# MB9AF31xK register map
Vendor: Cypress; File version: 2.1
MB9A310K Series package K
CPU: CM3 r2p1, little endian, MPU, no FPU, 4 interrupt priority bits
Registers are 32-bit, read-write, reset 0x0 unless marked. A register's access mark holds for its fields unless they carry their own. Offsets are from the block's base; lines under a group give offsets from that group; [hi:lo] are bit positions; {n}, {i} and the like mark numbered series; 'fields as' and 'values as' point back to an identical list; <NAME> marks a mode.

## Memory map
0x200E0000 WORKFLASH_IF size 0xC — WorkFlash Memory
0x40000000 FLASH_IF blocks up to offset 0x104 — Flash Memory
0x40000200 UNIQUE_ID size 0x8
0x40010000 CRG blocks up to offset 0x6C — Clock Unit Registers
0x40011000 HWWDT blocks up to offset 0xC04 — Hardware Watchdog Timer
0x40012000 SWWDT blocks up to offset 0xC04 — Software Watchdog Timer
0x40015000 DT blocks up to offset 0x3C — Dual Timer
0x40020000 MFT0 blocks up to offset 0xC2 — Multifunction Timer 0
0x40024000 MFT_PPG blocks up to offset 0x359 — PPG Configuration
0x40025000 BT0 blocks up to offset 0x12 — Base Timer 0
0x40025040 BT1 blocks up to offset 0x12 — Base Timer 1
0x40025080 BT2 blocks up to offset 0x12 — Base Timer 2
0x400250C0 BT3 blocks up to offset 0x12 — Base Timer 3
0x40025100 BTIOSEL03 blocks up to offset 0x2 — Base Timer I/O Select
0x40025200 BT4 blocks up to offset 0x12 — Base Timer 4
0x40025240 BT5 blocks up to offset 0x12 — Base Timer 5
0x40025280 BT6 blocks up to offset 0x12 — Base Timer 6
0x400252C0 BT7 blocks up to offset 0x12 — Base Timer 7
0x40025300 BTIOSEL47 blocks up to offset 0x2 — Base Timer I/O Select
0x40025F00 SBSSR blocks up to offset 0xFE — Software-based Simultaneous Startup Register
0x40026000 QPRC0 blocks up to offset 0x40 — Quadrature Position/Revolution Counter 0
0x40027000 ADC0 blocks up to offset 0x3D — ADC0 Registers
0x40027100 ADC1 blocks up to offset 0x3D — ADC1 Registers
0x4002E000 CRTRIM blocks up to offset 0x10 — CR Trimming Registers
0x40030000 EXTI blocks up to offset 0x1A — External Interrupt and NMI Control
0x40031000 INTREQ blocks up to offset 0x218 — Interrupts
0x40033000 GPIO blocks up to offset 0x740 — I/O Port Registers
0x40035000 LVD blocks up to offset 0x11 — Low-voltage Detection
0x40035100 DS blocks up to offset 0x810 — Low Power Consumption Mode
0x40036000 USBCLK blocks up to offset 0x31 — USB Clock
0x40038000 MFS0 blocks up to offset 0x1E — Multi-function Serial Interface 0
0x40038100 MFS1 blocks up to offset 0x1E — Multi-function Serial Interface 1
0x40038300 MFS3 blocks up to offset 0x1E — Multi-function Serial Interface 3
0x40038500 MFS5 blocks up to offset 0xE — Multi-function Serial Interface 5
0x40038800 MFS_NFC size 0x2 — I2C Auxiliary Noise Filter Setting Register
0x40039000 CRC blocks up to offset 0x10 — CRC Registers
0x4003A000 WC blocks up to offset 0x15 — Watch Counter
0x4003B000 RTC blocks up to offset 0x2A — REAL-TIME CLOCK
0x40040000 USB0 blocks up to offset 0x2176 — USB0 Function
0x40060000 DMAC blocks up to offset 0x90 — DMAC Registers

## Interrupts
0 CSV (CRG)
1 SWDT (SWWDT)
2 LVD
3 MFT0_2_WFG_DTIF (MFT0)
4 EXINT0_7 (EXTI)
5 EXINT8_31 (EXTI)
6 DT_QPRC0_2 (DT, QPRC0)
7 MFS0_RX (MFS0)
8 MFS0_TX (MFS0)
9 MFS1_RX (MFS1)
10 MFS1_TX (MFS1)
13 MFS3_RX (MFS3)
14 MFS3_TX (MFS3)
17 MFS5_RX (MFS5)
18 MFS5_TX (MFS5)
23 PPG00_02_04_08_10_12_16_18_20 (MFT_PPG)
24 TIM_WC_RTC (CRG, WC, RTC)
25 ADC0
26 ADC1
28 MFT0_2_FRT (MFT0)
29 MFT0_2_ICU (MFT0)
30 MFT0_2_OCU (MFT0)
31 BT0_7 (BT{n} (n=0..7))
34 USB0_F (USB0)
35 USB0_H_F (USB0)
{n+38} DMAC{n} (DMAC) (n=0..7)
47 FLASHIF (FLASH_IF)

## Further device data
mcutype=5

## FLASH_IF — Flash Memory
Base 0x40000000
0x00 FASZR reset 0x2 — Flash Access Size Register [BHW]
  [1:0] ASZ — Flash Access Size
0x04 FRWTR — Flash Read Wait Register [BHW]
  [1:0] RWT — Read Wait Cycle
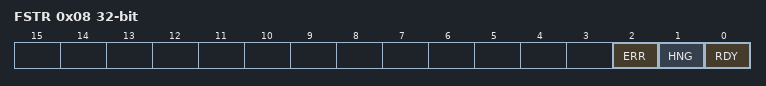
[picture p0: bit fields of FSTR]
0x08 FSTR ro (reset mask 0x6) — Flash Status Register [BHW]
  [2] ERR rw — Flash ECC Error
  [1] HNG — Flash Hang flag
  [0] RDY — Flash Rdy
0x10 FSYNDN — Flash Sync Down Register [BHW]
  [2:0] SD — Flash Sync
0x100 CRTRMM ro reset not defined — CR Trimming Data Mirror Register [BHW]
  [9:0] TRMM — CR Trimming Data Mirror

## Notices in the file
Copyright (C) 2013-2016, Cypress Semiconductor Corporation or a
subsidiary of Cypress Semiconductor Corporation.  All rights reserved.
This software, including source code, documentation and related
materials ("Software"), is owned by Cypress Semiconductor Corporation or
one of its subsidiaries ("Cypress") and is protected by and subject to
worldwide patent protection (United States and foreign), United States
copyright laws and international treaty provisions. Therefore, you may use
this Software only as provided in the license agreement accompanying the
software package from which you obtained this Software ("EULA").
If no EULA applies, Cypress hereby grants you a personal, non-exclusive,
non-transferable license to copy, modify, and compile the
Software source code solely for use in connection with Cypress's
integrated circuit products.  Any reproduction, modification, translation,
compilation, or representation of this Software except as specified
above is prohibited without the express written permission of Cypress.
Disclaimer: THIS SOFTWARE IS PROVIDED AS-IS, WITH NO
WARRANTY OF ANY KIND, EXPRESS OR IMPLIED, INCLUDING,
BUT NOT LIMITED TO, NONINFRINGEMENT, IMPLIED
WARRANTIES OF MERCHANTABILITY AND FITNESS FOR A
PARTICULAR PURPOSE. Cypress reserves the right to make
changes to the Software without notice. Cypress does not assume any
liability arising out of the application or use of the Software or any
product or circuit described in the Software. Cypress does not
authorize its products for use in any products where a malfunction or
failure of the Cypress product may reasonably be expected to result in
significant property damage, injury or death ("High Risk Product"). By
including Cypress's product in a High Risk Product, the manufacturer
of such system or application assumes all risk of such use and in doing
so agrees to indemnify Cypress against all liability.
